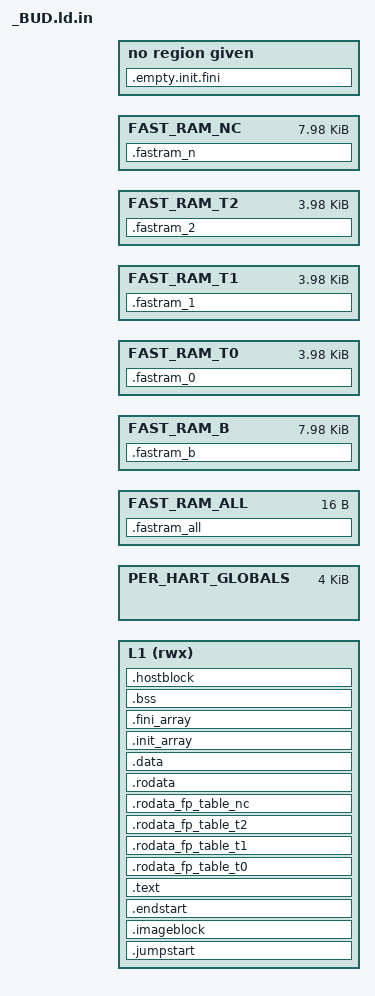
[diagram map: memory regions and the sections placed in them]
/* _BUD.ld:
  Thu Jan 15 01:58:15 2026 Work for an imageblock section for self-describing T6 code
  Fri Sep 26 15:57:42 2025 Try to add a 'transportblock' section
  Wed Aug 27 16:11:19 2025 Spike loader script on the road to non-trivial C++ on BH
 */

#include <dev_mem_map.h>

/* Define the entry point of your program.
 * This tells the linker which symbol should be the first instruction executed. */
ENTRY(_start)
PHDRS {
  attributes 0x70000003;
  text PT_LOAD;
  data PT_LOAD;
}
_fast_all_size = 16;

MEMORY
{
    /* Let's take half of L1 for our stuff, for now.. */
    L1 (rwx) : ORIGIN = MEM_L1_BASE, LENGTH = MEM_L1_SIZE/2

    /* we say 4K for per-hart-globals length since that's the minimum
       available and because that's all that imm12 can reach anyway.
       note for T0-T2 the stack will overlap the top of gp space */
    PER_HART_GLOBALS : ORIGIN = MEM_LOCAL_BASE, LENGTH = 4K

    FAST_RAM_ALL : ORIGIN = MEM_LOCAL_BASE, LENGTH = _fast_all_size
    FAST_RAM_B : ORIGIN = MEM_LOCAL_BASE+_fast_all_size, LENGTH = 8K-_fast_all_size
    FAST_RAM_T0 : ORIGIN = MEM_LOCAL_BASE+_fast_all_size, LENGTH = 4K-_fast_all_size
    FAST_RAM_T1 : ORIGIN = MEM_LOCAL_BASE+_fast_all_size, LENGTH = 4K-_fast_all_size
    FAST_RAM_T2 : ORIGIN = MEM_LOCAL_BASE+_fast_all_size, LENGTH = 4K-_fast_all_size
    FAST_RAM_NC : ORIGIN = MEM_LOCAL_BASE+_fast_all_size, LENGTH = 8K-_fast_all_size
}

/* Define how input sections are mapped to output sections and placed in memory. */
SECTIONS
{
    PROVIDE(__fast_start = ORIGIN(PER_HART_GLOBALS));

    /* (try to) use gp to help access fastram (not seeing any
       successful relaxations tho) */
    /*PROVIDE(__global_pointer$ = ORIGIN(PER_HART_GLOBALS) + 2K);*/
    PROVIDE(__global_pointer$ = ORIGIN(PER_HART_GLOBALS) + 2K - 128);

    /* stack in fastram (4 or 8K depending on hart) */
    PROVIDE(__stack_top4K = ORIGIN(PER_HART_GLOBALS) + 4K);
    PROVIDE(__stack_top8K = ORIGIN(PER_HART_GLOBALS) + 8K);

    /* stick fastram at the front of the private data! */
    .fastram_all (NOLOAD) : AT(ORIGIN(FAST_RAM_ALL)) { *(.fastram_all) } > FAST_RAM_ALL
    .fastram_b (NOLOAD) : AT(ORIGIN(FAST_RAM_B)) { *(.fastram_b) } > FAST_RAM_B
    .fastram_0 (NOLOAD) : AT(ORIGIN(FAST_RAM_T0)) { *(.fastram_0) } > FAST_RAM_T0
    .fastram_1 (NOLOAD) : AT(ORIGIN(FAST_RAM_T1)) { *(.fastram_1) } > FAST_RAM_T1
    .fastram_2 (NOLOAD) : AT(ORIGIN(FAST_RAM_T2)) { *(.fastram_2) } > FAST_RAM_T2
    .fastram_n (NOLOAD) : AT(ORIGIN(FAST_RAM_NC)) { *(.fastram_n) } > FAST_RAM_NC
    
  /* BEGIN STUFF CARGO-CULTED FROM MAIN.LD */
  .empty.init.fini :
  {
    /* Our elf loader checks that .empty* sections are empty, and
       can give a helpful error, rather than an ASSERT here.  */
    KEEP (*(.init .fini))
  } :text
  /* END STUFF CARGO-CULTED FROM MAIN.LD */

    /* toss stuff we don't want */
    /DISCARD/ : {
      *(.eh_frame)
    }

    /* Set the current location counter to the start of the RAM region.
     * All subsequent sections will be placed starting from this address. */
    . = ORIGIN(L1);
    . = ALIGN(4);

    /* .jumpstart section: Must land at 0 */
    .jumpstart :
    {
      *(.start)
    } > L1

    . = ALIGN(4);
    /* .imageblock section. Supposed to land at 0x18/21/word 6? Tue Aug 18 12:01:08 2026 NOW 0x40*/
    .imageblock : {
      *(.imageblock)
    } > L1

    /* .endstart section: (rest of _start) Follows imageblock */
    .endstart :
    {
      *(.endstart)
    } > L1

    /* .text section: Contains executable code.
     * This section will be placed after the start up code in L1. */
    .text :
    {
       KEEP(*(.text.startup)) # Keep specific startup code if any
       *(.text)               # All executable code from input files
       *(.text.*)             # All executable code from input files (e.g., from templates)
     } > L1

    .rodata_fp_table_t0 :
    {
       . = ALIGN(4);
       __start_rodata_fp_table_t0 = .;
       KEEP(*(SORT(.rodata_fp_table_t0*)))
       __end_rodata_fp_table_t0 = .;
    } > L1

    .rodata_fp_table_t1 :
    {
       . = ALIGN(4);
       __start_rodata_fp_table_t1 = .;
       KEEP(*(SORT(.rodata_fp_table_t1*)))
       __end_rodata_fp_table_t1 = .;
    } > L1

    .rodata_fp_table_t2 :
    {
       . = ALIGN(4);
       __start_rodata_fp_table_t2 = .;
       KEEP(*(SORT(.rodata_fp_table_t2*)))
       __end_rodata_fp_table_t2 = .;
    } > L1

    .rodata_fp_table_nc :
    {
       . = ALIGN(4);
       __start_rodata_fp_table_nc = .;
       KEEP(*(SORT(.rodata_fp_table_nc*)))
       __end_rodata_fp_table_nc = .;
    } > L1

    /* .rodata section: Contains read-only data (e.g., string literals, const variables).
     * Placed immediately after the .text section. */
    .rodata :
    {
       *(.rodata)             # Read-only data
       *(.rodata.*)
       *(.crossrodata)        /* Stuff that's rodata on cross/ but messed with on host/ */
    } > L1

    /* .data section: Contains initialized global and static variables.
     * Placed immediately after the .rodata section. */
    .data :
    {
      *(.sdata)              # 'normal' initialized data
      *(.data)               # Initialized data
      *(.data.*)

  /* MORE STUFF CARGO-CULTED FROM MAIN.LD */

     *(.rodata .rodata.* .gnu.linkonce.r.*)
     *(.rodata1)

    *(.dynamic)
    *(.data.rel.ro.local* .gnu.linkonce.d.rel.ro.local.*) *(.data.rel.ro .data.rel.ro.* .gnu.linkonce.d.rel.ro.*)
    *(.srodata.cst16) *(.srodata.cst8) *(.srodata.cst4) *(.srodata.cst2) *(.srodata .srodata.*)
    *(.sdata .sdata.* .gnu.linkonce.s.*)
    *(.sdata2 .sdata2.* .gnu.linkonce.s2.*)

    *(.data .data.* .gnu.linkonce.d.*)
    *(.data1)

    *(.got.plt) *(.igot.plt) *(.got) *(.igot)
  /* END STUFF CARGO-CULTED FROM MAIN.LD */

    } > L1

  /* --- NEW: C++ Static Constructor/Destructor Arrays --- */
  .init_array :
  {
    . = ALIGN(4);
    __init_array_start = .;
    KEEP(*(SORT_BY_INIT_PRIORITY(.init_array.*)))
    KEEP(*(.init_array))
    __init_array_end = .;
  } > L1

  .fini_array :
  {
    . = ALIGN(4);
    __fini_array_start = .;
    KEEP(*(SORT_BY_INIT_PRIORITY(.fini_array.*)))
    KEEP(*(.fini_array))
    __fini_array_end = .;
  } > L1

#if 0
  .empty.ctors.dtors :
  {
    /* We don't use .ctors/.dtors either (this still isn't the '90s), make sure there aren't any.  */
    KEEP (*(.ctors .ctors.* .dtors .dtors.*))
  } :data
  .empty.init_array.fini_array :
  {
    /* We don't support global static constructors or destructors. make sure there aren't any.  */
    KEEP (*(.preinit_array))
    KEEP (*(SORT_BY_INIT_PRIORITY(.init_array.*)))
    KEEP (*(.init_array))
    KEEP (*(SORT_BY_INIT_PRIORITY(.fini_array.*)))
    KEEP (*(.fini_array))
  } :data
#endif

    /* .bss section: Contains uninitialized global and static variables.
     * These variables are typically zero-initialized by startup code.
     * Placed immediately after the .data section. */
    .bss :
    {
      . = ALIGN(4);
      PROVIDE(__bss_start = .);
      *(.sbss)               # 'normal' uninitialized data? wth?
      *(.bss)                # Uninitialized data
      *(.bss.*)
      *(COMMON)              # Common symbols (uninitialized data)
      . = ALIGN(4);
      PROVIDE(__bss_end = .);
    } > L1

/*
    .transportblock :
    {
      . = ALIGN(16);
      PROVIDE(__transportblock_all_start = .);
      *(.transportblock)
      . = ALIGN(16);
      PROVIDE(__transportblock_all_end = .);
      __transportblock_all_size = ABSOLUTE(__transportblock_all_end - __transportblock_all_start);
    } > L1

    .transportblocklog :
    {
      . = ALIGN(16);
      PROVIDE(__transportblock_log_start = .);
      *(.transportblocklog)
      . = ALIGN(16);
      PROVIDE(__transportblock_log_end = .);
      __transportblock_log_size = ABSOLUTE(__transportblock_log_end - __transportblock_log_start);
    } > L1

    .transportblockew :
    {
      . = ALIGN(16);
      PROVIDE(__transportblock_ew_start = .);
      *(.transportblockew)
      . = ALIGN(16);
      PROVIDE(__transportblock_ew_end = .);
      __transportblock_ew_size = ABSOLUTE(__transportblock_ew_end - __transportblock_ew_start);
    } > L1

    .imageblock :
    {
      . = ALIGN(16);
      PROVIDE(__imageblock_start = .);
      *(.imageblock)
      PROVIDE(__imageblock_end = .);
      __imageblock_size = ABSOLUTE(__imageblock_end - __imageblock_start);
      PROVIDE(_end = .);
    } > L1
*/

    /* HOSTBLOCK MUST BE LAST IN IMAGE, because
       host/src/CodeManager.cpp looks for it at
       codesize-sizeof(HostBlock)! */
    
    .hostblock :
    {
      . = ALIGN(16);
      PROVIDE(__hostblock_start = .);
      *(.hostblock)
      PROVIDE(__hostblock_end = .);
      __hostblock_size = ABSOLUTE(__hostblock_end - __hostblock_start);
      PROVIDE(_end = .);
    } > L1

 }
 
